VERSION "1.0"
NS_ :

BS_:

BU_: ECU

BO_ 1536 THROTTLE: 4 ECU
 SG_ THROTTLE_signal : 0|8@1+ (1,0) [0|255] ""  ECU

BO_ 1537 BRAKE: 4 ECU
 SG_ BRAKE_signal : 0|8@1+ (1,0) [0|255] ""  ECU

BO_ 1538 STEER: 4 ECU
 SG_ STEER_signal : 0|8@1+ (1,0) [0|255] ""  ECU

BO_ 1539 REVERSE: 1 ECU
 SG_ REVERSE_signal : 0|8@1+ (1,0) [0|255] ""  ECU

BO_ 1540 HAND_BRAKE: 1 ECU
 SG_ HAND_BRAKE_signal : 0|8@1+ (1,0) [0|255] ""  ECU

BO_ 1541 AUTOPILOT: 4 ECU
 SG_ AUTOPILOT_signal : 0|8@1+ (1,0) [0|255] ""  ECU

BO_ 1542 MANUAL_TRANSMISSION: 1 ECU
 SG_ MANUAL_TRANSMISSION_signal : 0|8@1+ (1,0) [0|255] ""  ECU

BO_ 1543 GEAR: 4 ECU
 SG_ GEAR_signal : 0|8@1+ (1,0) [0|255] ""  ECU

BO_ 1548 DOORS: 1 ECU
 SG_ DOORS_signal : 0|8@1+ (1,0) [0|255] ""  ECU

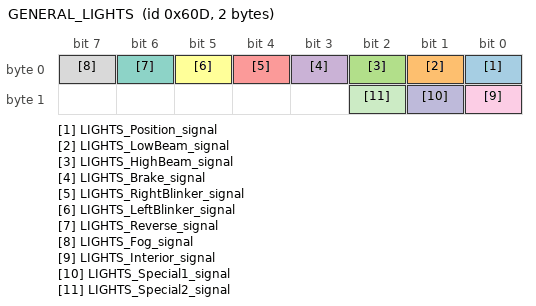
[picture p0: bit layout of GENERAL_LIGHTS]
BO_ 1549 GENERAL_LIGHTS: 2 ECU
 SG_ LIGHTS_Position_signal     : 0|1@1+  (1,0) [0|1] ""  ECU
 SG_ LIGHTS_LowBeam_signal      : 1|1@1+  (1,0) [0|1] ""  ECU
 SG_ LIGHTS_HighBeam_signal     : 2|1@1+  (1,0) [0|1] ""  ECU
 SG_ LIGHTS_Brake_signal        : 3|1@1+  (1,0) [0|1] ""  ECU
 SG_ LIGHTS_RightBlinker_signal : 4|1@1+  (1,0) [0|1] ""  ECU
 SG_ LIGHTS_LeftBlinker_signal  : 5|1@1+  (1,0) [0|1] ""  ECU
 SG_ LIGHTS_Reverse_signal      : 6|1@1+  (1,0) [0|1] ""  ECU
 SG_ LIGHTS_Fog_signal          : 7|1@1+  (1,0) [0|1] ""  ECU
 SG_ LIGHTS_Interior_signal     : 8|1@1+  (1,0) [0|1] ""  ECU
 SG_ LIGHTS_Special1_signal     : 9|1@1+  (1,0) [0|1] ""  ECU
 SG_ LIGHTS_Special2_signal     : 10|1@1+ (1,0) [0|1] ""  ECU

BA_DEF_ BO_ "GenMsgCycleTime" INT 0 10000;

BA_DEF_DEF_ "GenMsgCycleTime" 0;

BA_ "GenMsgCycleTime" BO_ 1536 100;
BA_ "GenMsgCycleTime" BO_ 1537 100;
BA_ "GenMsgCycleTime" BO_ 1538 100;
BA_ "GenMsgCycleTime" BO_ 1539 200;
BA_ "GenMsgCycleTime" BO_ 1540 200;
BA_ "GenMsgCycleTime" BO_ 1541 500;
BA_ "GenMsgCycleTime" BO_ 1542 500;
BA_ "GenMsgCycleTime" BO_ 1543 200;
